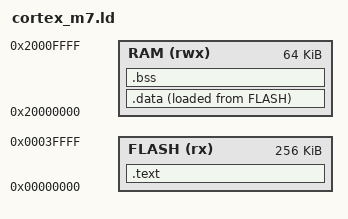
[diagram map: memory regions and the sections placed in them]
/* =============================================================
 *  Linker Script — ARM Cortex-M7 (QEMU mps2-an500)
 *  Flash : 0x00000000, 4 Mo
 *  RAM   : 0x20000000, 4 Mo
 * ============================================================= */

MEMORY {
    FLASH (rx)  : ORIGIN = 0x00000000, LENGTH = 256K
    RAM   (rwx) : ORIGIN = 0x20000000, LENGTH = 64K
}

ENTRY(Reset_Handler)

SECTIONS {
    .text : {
        KEEP(*(.isr_vector))
        *(.text*)
        *(.rodata*)
        . = ALIGN(4);
        _sidata = .;
    } > FLASH

    .data : {
        _sdata = .;
        *(.data*)
        . = ALIGN(4);
        _edata = .;
    } > RAM AT > FLASH

    .bss : {
        _sbss = .;
        *(.bss*)
        *(COMMON)
        . = ALIGN(4);
        _ebss = .;
    } > RAM

    _estack = ORIGIN(RAM) + LENGTH(RAM);
}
